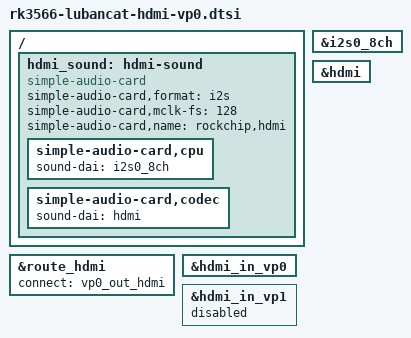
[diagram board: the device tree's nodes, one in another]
// SPDX-License-Identifier: (GPL-2.0+ OR MIT)
/{
	hdmi_sound: hdmi-sound {
		compatible = "simple-audio-card";
		simple-audio-card,format = "i2s";
		simple-audio-card,mclk-fs = <128>;
		simple-audio-card,name = "rockchip,hdmi";
		status = "okay";

		simple-audio-card,cpu {
			sound-dai = <&i2s0_8ch>;
		};

		simple-audio-card,codec {
			sound-dai = <&hdmi>;
		};
	};
};

&i2s0_8ch {
	status = "okay";
};

&route_hdmi {
	status = "okay";
	connect = <&vp0_out_hdmi>;
};

&hdmi_in_vp0 {
	status = "okay";
};

&hdmi_in_vp1 {
	status = "disabled";
};

&hdmi {
	status = "okay";
};
